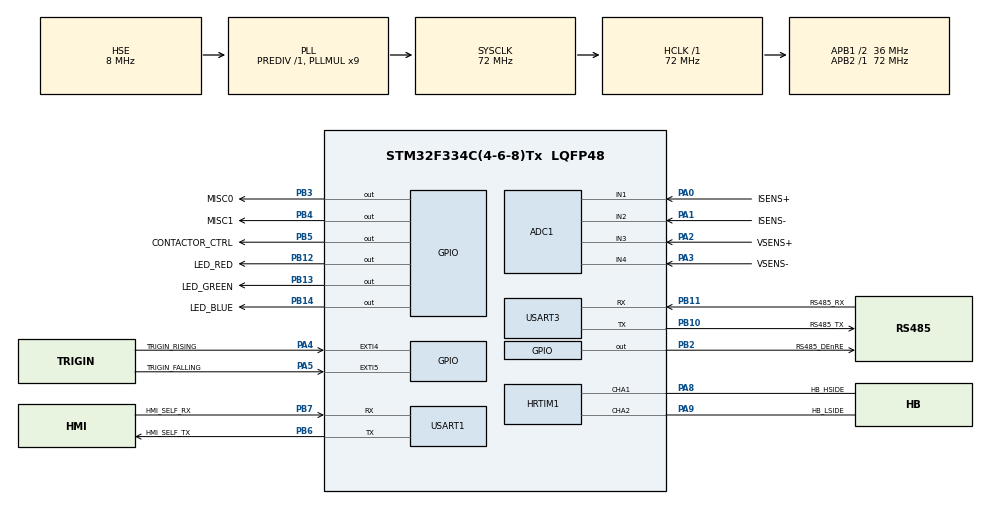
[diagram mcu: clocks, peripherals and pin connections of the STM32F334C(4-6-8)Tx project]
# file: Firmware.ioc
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ADC1.Channel-0\#ChannelRegularConversion=ADC_CHANNEL_1
ADC1.Channel-1\#ChannelRegularConversion=ADC_CHANNEL_3
ADC1.ClockPrescaler=ADC_CLOCK_ASYNC_DIV1
ADC1.DMAContinuousRequests=ENABLE
ADC1.EOCSelection=ADC_EOC_SEQ_CONV
ADC1.ExternalTrigConv=ADC_EXTERNALTRIGCONVHRTIM_TRG1
ADC1.NbrOfConversion=2
ADC1.NbrOfConversionFlag=1
ADC1.Offset-0\#ChannelRegularConversion=0
ADC1.Offset-1\#ChannelRegularConversion=0
ADC1.OffsetNumber-0\#ChannelRegularConversion=ADC_OFFSET_NONE
ADC1.OffsetNumber-1\#ChannelRegularConversion=ADC_OFFSET_NONE
ADC1.Rank-0\#ChannelRegularConversion=1
ADC1.Rank-1\#ChannelRegularConversion=2
ADC1.SamplingTime-0\#ChannelRegularConversion=ADC_SAMPLETIME_19CYCLES_5
ADC1.SamplingTime-1\#ChannelRegularConversion=ADC_SAMPLETIME_19CYCLES_5
ADC1.SingleDiff-0\#ChannelRegularConversion=ADC_DIFFERENTIAL_ENDED
ADC1.SingleDiff-1\#ChannelRegularConversion=ADC_DIFFERENTIAL_ENDED
ADC1.SubFamily=STM32F334x8
ADC1.master=1
Dma.ADC1.0.Direction=DMA_PERIPH_TO_MEMORY
Dma.ADC1.0.Instance=DMA1_Channel1
Dma.ADC1.0.MemDataAlignment=DMA_MDATAALIGN_HALFWORD
Dma.ADC1.0.MemInc=DMA_MINC_ENABLE
Dma.ADC1.0.Mode=DMA_CIRCULAR
Dma.ADC1.0.PeriphDataAlignment=DMA_PDATAALIGN_HALFWORD
Dma.ADC1.0.PeriphInc=DMA_PINC_DISABLE
Dma.ADC1.0.Priority=DMA_PRIORITY_MEDIUM
Dma.Request0=ADC1
HRTIM1.ADCTrigger1_Source1=HRTIM_ADCTRIGGEREVENT13_TIMERB_CMP2
HRTIM1.ADCTrigger_Id1=HRTIM_ADCTRIGGER_1
HRTIM1.ADCTrigger_Id2=__NULL
HRTIM1.ADCTrigger_Id3=__NULL
HRTIM1.CompareUnit1-No_output_TB=__NULL
HRTIM1.CompareUnit1-Output_TA1TA2=HRTIM_COMPAREUNIT_1
HRTIM1.CompareUnit2-No_output_TB=HRTIM_COMPAREUNIT_2
HRTIM1.CompareUnit2-Output_TA1TA2=HRTIM_COMPAREUNIT_2
HRTIM1.CompareValue1-Output_TA1TA2=0x0018
HRTIM1.CompareValue2-No_output_TB=0x8000
HRTIM1.Configuration_TA=Waveform
HRTIM1.DeadTimeInsertion-Output_TA1TA2=HRTIM_TIMDEADTIMEINSERTION_ENABLED
HRTIM1.Enable_FaultLine1=HRTIM_FAULTMODECTL_DISABLED
HRTIM1.FallingLock-Output_TA1TA2=HRTIM_TIMDEADTIME_FALLINGLOCK_READONLY
HRTIM1.FallingSign-Output_TA1TA2=HRTIM_TIMDEADTIME_FALLINGSIGN_POSITIVE
HRTIM1.FallingSignLock-Output_TA1TA2=HRTIM_TIMDEADTIME_FALLINGSIGNLOCK_READONLY
HRTIM1.FallingValue-Output_TA1TA2=144
HRTIM1.FaultEnable_Source1-No_output_TB=HRTIM_TIMFAULTENABLE_FAULT1
HRTIM1.FaultEnable_Source1-Output_TA1TA2=HRTIM_TIMFAULTENABLE_NONE
HRTIM1.FaultLevel1-Output_TA1TA2=HRTIM_OUTPUTFAULTLEVEL_NONE
HRTIM1.FaultLevel2-Output_TA1TA2=HRTIM_OUTPUTFAULTLEVEL_NONE
HRTIM1.FaultLock-Output_TA1TA2=HRTIM_TIMFAULTLOCK_READONLY
HRTIM1.Fault_Line1=__NULL
HRTIM1.Filter_FaultLine1=HRTIM_FAULTFILTER_12
HRTIM1.Lock_FaultLine1=HRTIM_FAULTLOCK_READONLY
HRTIM1.NumberADCTriggerSource1=1
HRTIM1.NumberFaultEnable-No_output_TB=0
HRTIM1.NumberFaultEnable-Output_TA1TA2=0
HRTIM1.NumberResetSource1-Output_TA1TA2=1
HRTIM1.NumberResetTrigger-No_output_TB=1
HRTIM1.NumberSetSource1-Output_TA1TA2=1
HRTIM1.NumberUpdateTrigger-No_output_TB=1
HRTIM1.ORingUpdateSource_ADCTrigger1=HRTIM_ADCTRIGGERUPDATE_TIMER_B
HRTIM1.Polarity1-Output_TA1TA2=HRTIM_OUTPUTPOLARITY_LOW
HRTIM1.Polarity2-Output_TA1TA2=HRTIM_OUTPUTPOLARITY_LOW
HRTIM1.PreloadEnable-No_output_TB=HRTIM_PRELOAD_ENABLED
HRTIM1.PreloadEnable-Output_TA1TA2=HRTIM_PRELOAD_ENABLED
HRTIM1.PrescalerDead-Output_TA1TA2=HRTIM_TIMDEADTIME_PRESCALERRATIO_DIV1
HRTIM1.PrescalerRatio_TA=HRTIM_PRESCALERRATIO_MUL8
HRTIM1.PrescalerRatio_TB=HRTIM_PRESCALERRATIO_MUL8
HRTIM1.ResetOutput1_Source1-Output_TA1TA2=HRTIM_OUTPUTRESET_TIMCMP2
HRTIM1.ResetTrigger1-No_output_TB=HRTIM_TIMRESETTRIGGER_OTHER1_CMP1
HRTIM1.ResetUpdate-No_output_TB=HRTIM_TIMUPDATEONRESET_DISABLED
HRTIM1.ResetUpdate-Output_TA1TA2=HRTIM_TIMUPDATEONRESET_ENABLED
HRTIM1.RisingLock-Output_TA1TA2=HRTIM_TIMDEADTIME_RISINGLOCK_READONLY
HRTIM1.RisingSignLock-Output_TA1TA2=HRTIM_TIMDEADTIME_RISINGSIGNLOCK_READONLY
HRTIM1.RisingValue-Output_TA1TA2=144
HRTIM1.SetOutput1_Source1-Output_TA1TA2=HRTIM_OUTPUTSET_TIMPER
HRTIM1.UpdateTrigger1-No_output_TB=HRTIM_TIMUPDATETRIGGER_TIMER_A
Mcu.Family=STM32F3
Mcu.Name=STM32F334C(4-6-8)Tx
Mcu.Package=LQFP48
Mcu.UserConstants=MCU_CLOCK_FREQ,72000000;TIM3_CLOCK_FREQ,MCU_CLOCK_FREQ;TIM3_PRESCALER,71;DEFAULT_LINE_FREQ,50
NVIC.DMA1_Channel1_IRQn=true\:1\:0\:true\:false\:true\:false\:true
NVIC.EXTI4_IRQn=true\:2\:0\:true\:false\:true\:true\:true
NVIC.EXTI9_5_IRQn=true\:2\:0\:true\:false\:true\:true\:true
NVIC.PriorityGroup=NVIC_PRIORITYGROUP_4
PA0.GPIO_Label=ISENS+
PA0.Mode=IN1-Differential
PA0.Signal=ADC1_IN1
PA1.GPIO_Label=ISENS-
PA1.Mode=IN1-Differential
PA1.Signal=ADC1_IN2
PA13.Mode=Serial_Wire
PA13.Signal=SYS_JTMS-SWDIO
PA14.Mode=Serial_Wire
PA14.Signal=SYS_JTCK-SWCLK
PA2.GPIO_Label=VSENS+
PA2.Mode=IN3-Differential
PA2.Signal=ADC1_IN3
PA3.GPIO_Label=VSENS-
PA3.Mode=IN3-Differential
PA3.Signal=ADC1_IN4
PA4.GPIO_Label=TRIGIN_RISING
PA4.GPIO_PuPd=GPIO_PULLDOWN
PA4.Signal=GPXTI4
PA5.GPIO_Label=TRIGIN_FALLING
PA5.GPIO_PuPd=GPIO_PULLDOWN
PA5.Signal=GPXTI5
PA8.GPIO_Label=HB_HSIDE
PA8.Mode=Output_TA1TA2
PA8.Signal=HRTIM1_CHA1
PA9.GPIO_Label=HB_LSIDE
PA9.Mode=Output_TA1TA2
PA9.Signal=HRTIM1_CHA2
PB10.GPIO_Label=RS485_TX
PB10.Mode=Asynchronous
PB10.Signal=USART3_TX
PB11.GPIO_Label=RS485_RX
PB11.Mode=Asynchronous
PB11.Signal=USART3_RX
PB12.GPIO_Label=LED_RED
PB12.Signal=GPIO_Output
PB13.GPIO_Label=LED_GREEN
PB13.Signal=GPIO_Output
PB14.GPIO_Label=LED_BLUE
PB14.Signal=GPIO_Output
PB2.GPIO_Label=RS485_DEnRE
PB2.GPIO_Speed=GPIO_SPEED_FREQ_MEDIUM
PB2.PinState=GPIO_PIN_RESET
PB2.Signal=GPIO_Output
PB3.GPIO_Label=MISC0
PB3.Signal=GPIO_Output
PB4.GPIO_Label=MISC1
PB4.Signal=GPIO_Output
PB5.GPIO_Label=CONTACTOR_CTRL
PB5.Signal=GPIO_Output
PB6.GPIO_Label=HMI_SELF_TX
PB6.Mode=Asynchronous
PB6.Signal=USART1_TX
PB7.GPIO_Label=HMI_SELF_RX
PB7.Mode=Asynchronous
PB7.Signal=USART1_RX
PF0\ /\ OSC_IN.Mode=HSE-External-Oscillator
PF0\ /\ OSC_IN.Signal=RCC_OSC_IN
PF1\ /\ OSC_OUT.Mode=HSE-External-Oscillator
PF1\ /\ OSC_OUT.Signal=RCC_OSC_OUT
ProjectManager.HeapSize=0x200
ProjectManager.StackSize=0x400
ProjectManager.TargetToolchain=Makefile
RCC.AHBFreq_Value=72000000
RCC.APB1CLKDivider=RCC_HCLK_DIV2
RCC.APB1Freq_Value=36000000
RCC.APB1TimFreq_Value=72000000
RCC.APB2Freq_Value=72000000
RCC.APB2TimFreq_Value=72000000
RCC.CortexFreq_Value=72000000
RCC.HCLKFreq_Value=72000000
RCC.HRTIMSelection=RCC_HRTIM1CLK_PLLCLK
RCC.HSE_VALUE=8000000
RCC.HSI_VALUE=8000000
RCC.LSE_VALUE=32768
RCC.PLLMUL=RCC_PLL_MUL9
RCC.PLLSourceVirtual=RCC_PLLSOURCE_HSE
RCC.SYSCLKFreq_VALUE=72000000
RCC.SYSCLKSourceVirtual=RCC_SYSCLKSOURCE_PLLCLK
USART1.VirtualMode-Asynchronous=VM_ASYNC
USART3.VirtualMode-Asynchronous=VM_ASYNC
VP_HRTIM1_VS_hrtimTimerBNoOutput.Mode=No_output_TB
board=custom

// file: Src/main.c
/* USER CODE BEGIN Header */
/**
  ******************************************************************************
  * @file           : main.c
  * @brief          : Main program body
  ******************************************************************************
  * @attention
  *
  * <h2><center>&copy; Copyright (c) 2020 STMicroelectronics.
  * All rights reserved.</center></h2>
  *
  * This software component is licensed by ST under BSD 3-Clause license,
  * the "License"; You may not use this file except in compliance with the
  * License. You may obtain a copy of the License at:
  *                        opensource.org/licenses/BSD-3-Clause
  *
  ******************************************************************************
  */
  /* USER CODE END Header */

  /* Includes ------------------------------------------------------------------*/
#include "main.h"
#include "lattice.h"
#include "eeprom_emulator.h"

ADC_HandleTypeDef hadc1;
DMA_HandleTypeDef hdma_adc1;

HRTIM_HandleTypeDef hhrtim1;

UART_HandleTypeDef huart1;
UART_HandleTypeDef huart3;

void SystemClock_Config(void);
static void MX_GPIO_Init(void);
static void MX_DMA_Init(void);
static void MX_HRTIM1_Init(void);
static void MX_ADC1_Init(void);
static void MX_USART1_UART_Init(void);
static void MX_USART3_UART_Init(void);

int main(void)
{

    /* MCU Configuration--------------------------------------------------------*/

    /* Reset of all peripherals, Initializes the Flash interface and the Systick. */
    HAL_Init();

    /* Configure the system clock */
    SystemClock_Config();

    /* Initialize all configured peripherals */
    MX_GPIO_Init();
    MX_DMA_Init();
    MX_HRTIM1_Init();
    MX_ADC1_Init();
    MX_USART1_UART_Init();
    MX_USART3_UART_Init();

    /* USER CODE BEGIN 2 */
    HAL_Delay(STARTUP_DELAY_IN_MS);

    // Turn on the contactor.
    EepromEmulator_Init();
    HAL_GPIO_WritePin(CONTACTOR_CTRL_GPIO_Port, CONTACTOR_CTRL_Pin, GPIO_PIN_RESET);
    Lattice_Start();
    /* USER CODE END 2 */

    /* Infinite loop */
    /* USER CODE BEGIN WHILE */
    while (1)
    {
        Lattice_Execute();
        /* USER CODE END WHILE */

    }
}

void SystemClock_Config(void)
{
    RCC_OscInitTypeDef RCC_OscInitStruct ={ 0 };
    RCC_ClkInitTypeDef RCC_ClkInitStruct ={ 0 };
    RCC_PeriphCLKInitTypeDef PeriphClkInit ={ 0 };

    /** Initializes the CPU, AHB and APB busses clocks
    */
    RCC_OscInitStruct.OscillatorType = RCC_OSCILLATORTYPE_HSE;
    RCC_OscInitStruct.HSEState = RCC_HSE_ON;
    RCC_OscInitStruct.HSEPredivValue = RCC_HSE_PREDIV_DIV1;
    RCC_OscInitStruct.HSIState = RCC_HSI_ON;
    RCC_OscInitStruct.PLL.PLLState = RCC_PLL_ON;
    RCC_OscInitStruct.PLL.PLLSource = RCC_PLLSOURCE_HSE;
    RCC_OscInitStruct.PLL.PLLMUL = RCC_PLL_MUL9;
    if (HAL_RCC_OscConfig(&RCC_OscInitStruct) != HAL_OK)
    {
        Error_Handler();
    }
    /** Initializes the CPU, AHB and APB busses clocks
    */
    RCC_ClkInitStruct.ClockType = RCC_CLOCKTYPE_HCLK | RCC_CLOCKTYPE_SYSCLK | RCC_CLOCKTYPE_PCLK1 | RCC_CLOCKTYPE_PCLK2;
    RCC_ClkInitStruct.SYSCLKSource = RCC_SYSCLKSOURCE_PLLCLK;
    RCC_ClkInitStruct.AHBCLKDivider = RCC_SYSCLK_DIV1;
    RCC_ClkInitStruct.APB1CLKDivider = RCC_HCLK_DIV2;
    RCC_ClkInitStruct.APB2CLKDivider = RCC_HCLK_DIV1;

    if (HAL_RCC_ClockConfig(&RCC_ClkInitStruct, FLASH_LATENCY_2) != HAL_OK)
    {
        Error_Handler();
    }
    PeriphClkInit.PeriphClockSelection = RCC_PERIPHCLK_HRTIM1 | RCC_PERIPHCLK_USART1;
    PeriphClkInit.Usart1ClockSelection = RCC_USART1CLKSOURCE_PCLK1;
    PeriphClkInit.Hrtim1ClockSelection = RCC_HRTIM1CLK_PLLCLK;
    if (HAL_RCCEx_PeriphCLKConfig(&PeriphClkInit) != HAL_OK)
    {
        Error_Handler();
    }
}

static void MX_ADC1_Init(void)
{

    ADC_MultiModeTypeDef multimode ={ 0 };
    ADC_ChannelConfTypeDef sConfig ={ 0 };

    /** Common config
    */
    hadc1.Instance = ADC1;
    hadc1.Init.ClockPrescaler = ADC_CLOCK_SYNC_PCLK_DIV2;
    hadc1.Init.Resolution = ADC_RESOLUTION_12B;
    hadc1.Init.ScanConvMode = ADC_SCAN_ENABLE;
    hadc1.Init.ContinuousConvMode = DISABLE;
    hadc1.Init.DiscontinuousConvMode = DISABLE;
    hadc1.Init.ExternalTrigConvEdge = ADC_EXTERNALTRIGCONVEDGE_RISING;
    hadc1.Init.ExternalTrigConv = ADC_EXTERNALTRIGCONVHRTIM_TRG1;
    hadc1.Init.DataAlign = ADC_DATAALIGN_RIGHT;
    hadc1.Init.NbrOfConversion = 2;
    hadc1.Init.DMAContinuousRequests = ENABLE;
    hadc1.Init.EOCSelection = ADC_EOC_SEQ_CONV;
    hadc1.Init.LowPowerAutoWait = DISABLE;
    hadc1.Init.Overrun = ADC_OVR_DATA_OVERWRITTEN;
    if (HAL_ADC_Init(&hadc1) != HAL_OK)
    {
        Error_Handler();
    }
    /** Configure the ADC multi-mode
    */
    multimode.Mode = ADC_MODE_INDEPENDENT;
    if (HAL_ADCEx_MultiModeConfigChannel(&hadc1, &multimode) != HAL_OK)
    {
        Error_Handler();
    }
    /** Configure Regular Channel
    */
    sConfig.Channel = ADC_CHANNEL_1;
    sConfig.Rank = ADC_REGULAR_RANK_1;
    sConfig.SingleDiff = ADC_DIFFERENTIAL_ENDED;
    sConfig.SamplingTime = ADC_SAMPLETIME_19CYCLES_5;
    sConfig.OffsetNumber = ADC_OFFSET_NONE;
    sConfig.Offset = 0;
    if (HAL_ADC_ConfigChannel(&hadc1, &sConfig) != HAL_OK)
    {
        Error_Handler();
    }
    /** Configure Regular Channel
    */
    sConfig.Channel = ADC_CHANNEL_3;
    sConfig.Rank = ADC_REGULAR_RANK_2;
    if (HAL_ADC_ConfigChannel(&hadc1, &sConfig) != HAL_OK)
    {
        Error_Handler();
    }
}

static void MX_HRTIM1_Init(void)
{

    HRTIM_ADCTriggerCfgTypeDef pADCTriggerCfg ={ 0 };
    HRTIM_TimeBaseCfgTypeDef pTimeBaseCfg ={ 0 };
    HRTIM_TimerCfgTypeDef pTimerCfg ={ 0 };
    HRTIM_CompareCfgTypeDef pCompareCfg ={ 0 };
    HRTIM_DeadTimeCfgTypeDef pDeadTimeCfg ={ 0 };
    HRTIM_OutputCfgTypeDef pOutputCfg ={ 0 };

    hhrtim1.Instance = HRTIM1;
    hhrtim1.Init.HRTIMInterruptResquests = HRTIM_IT_NONE;
    hhrtim1.Init.SyncOptions = HRTIM_SYNCOPTION_NONE;
    if (HAL_HRTIM_Init(&hhrtim1) != HAL_OK)
    {
        Error_Handler();
    }
    if (HAL_HRTIM_DLLCalibrationStart(&hhrtim1, HRTIM_CALIBRATIONRATE_14) != HAL_OK)
    {
        Error_Handler();
    }
    if (HAL_HRTIM_PollForDLLCalibration(&hhrtim1, 10) != HAL_OK)
    {
        Error_Handler();
    }
    pADCTriggerCfg.UpdateSource = HRTIM_ADCTRIGGERUPDATE_TIMER_B;
    pADCTriggerCfg.Trigger = HRTIM_ADCTRIGGEREVENT13_TIMERB_CMP2;
    if (HAL_HRTIM_ADCTriggerConfig(&hhrtim1, HRTIM_ADCTRIGGER_1, &pADCTriggerCfg) != HAL_OK)
    {
        Error_Handler();
    }
    pTimeBaseCfg.Period = 0xFFF7;
    pTimeBaseCfg.RepetitionCounter = 0x00;
    pTimeBaseCfg.PrescalerRatio = HRTIM_PRESCALERRATIO_MUL8;
    pTimeBaseCfg.Mode = HRTIM_MODE_CONTINUOUS;
    if (HAL_HRTIM_TimeBaseConfig(&hhrtim1, HRTIM_TIMERINDEX_TIMER_A, &pTimeBaseCfg) != HAL_OK)
    {
        Error_Handler();
    }
    pTimerCfg.InterruptRequests = HRTIM_TIM_IT_NONE;
    pTimerCfg.DMARequests = HRTIM_TIM_DMA_NONE;
    pTimerCfg.DMASrcAddress = 0x0000;
    pTimerCfg.DMADstAddress = 0x0000;
    pTimerCfg.DMASize = 0x1;
    pTimerCfg.HalfModeEnable = HRTIM_HALFMODE_DISABLED;
    pTimerCfg.StartOnSync = HRTIM_SYNCSTART_DISABLED;
    pTimerCfg.ResetOnSync = HRTIM_SYNCRESET_DISABLED;
    pTimerCfg.DACSynchro = HRTIM_DACSYNC_NONE;
    pTimerCfg.PreloadEnable = HRTIM_PRELOAD_ENABLED;
    pTimerCfg.UpdateGating = HRTIM_UPDATEGATING_INDEPENDENT;
    pTimerCfg.BurstMode = HRTIM_TIMERBURSTMODE_MAINTAINCLOCK;
    pTimerCfg.RepetitionUpdate = HRTIM_UPDATEONREPETITION_DISABLED;
    pTimerCfg.PushPull = HRTIM_TIMPUSHPULLMODE_DISABLED;
    pTimerCfg.FaultEnable = HRTIM_TIMFAULTENABLE_NONE;
    pTimerCfg.FaultLock = HRTIM_TIMFAULTLOCK_READONLY;
    pTimerCfg.DeadTimeInsertion = HRTIM_TIMDEADTIMEINSERTION_ENABLED;
    pTimerCfg.DelayedProtectionMode = HRTIM_TIMER_A_B_C_DELAYEDPROTECTION_DISABLED;
    pTimerCfg.UpdateTrigger = HRTIM_TIMUPDATETRIGGER_NONE;
    pTimerCfg.ResetTrigger = HRTIM_TIMRESETTRIGGER_NONE;
    pTimerCfg.ResetUpdate = HRTIM_TIMUPDATEONRESET_ENABLED;
    if (HAL_HRTIM_WaveformTimerConfig(&hhrtim1, HRTIM_TIMERINDEX_TIMER_A, &pTimerCfg) != HAL_OK)
    {
        Error_Handler();
    }
    pTimerCfg.DMASrcAddress = 0x0000;
    pTimerCfg.DMADstAddress = 0x0000;
    pTimerCfg.DMASize = 0x1;
    pTimerCfg.FaultLock = HRTIM_TIMFAULTLOCK_READWRITE;
    pTimerCfg.DeadTimeInsertion = HRTIM_TIMDEADTIMEINSERTION_DISABLED;
    pTimerCfg.UpdateTrigger = HRTIM_TIMUPDATETRIGGER_TIMER_A;
    pTimerCfg.ResetTrigger = HRTIM_TIMRESETTRIGGER_OTHER1_CMP1;
    pTimerCfg.ResetUpdate = HRTIM_TIMUPDATEONRESET_DISABLED;
    if (HAL_HRTIM_WaveformTimerConfig(&hhrtim1, HRTIM_TIMERINDEX_TIMER_B, &pTimerCfg) != HAL_OK)
    {
        Error_Handler();
    }
    pCompareCfg.CompareValue = 0x0018;
    if (HAL_HRTIM_WaveformCompareConfig(&hhrtim1, HRTIM_TIMERINDEX_TIMER_A, HRTIM_COMPAREUNIT_1, &pCompareCfg) != HAL_OK)
    {
        Error_Handler();
    }
    pCompareCfg.CompareValue = 0xFFF7;
    pCompareCfg.AutoDelayedMode = HRTIM_AUTODELAYEDMODE_REGULAR;
    pCompareCfg.AutoDelayedTimeout = 0x0000;

    if (HAL_HRTIM_WaveformCompareConfig(&hhrtim1, HRTIM_TIMERINDEX_TIMER_A, HRTIM_COMPAREUNIT_2, &pCompareCfg) != HAL_OK)
    {
        Error_Handler();
    }
    pCompareCfg.CompareValue = 0x8000;
    pCompareCfg.AutoDelayedTimeout = 0x0000;

    if (HAL_HRTIM_WaveformCompareConfig(&hhrtim1, HRTIM_TIMERINDEX_TIMER_B, HRTIM_COMPAREUNIT_2, &pCompareCfg) != HAL_OK)
    {
        Error_Handler();
    }
    pDeadTimeCfg.Prescaler = HRTIM_TIMDEADTIME_PRESCALERRATIO_DIV1;
    pDeadTimeCfg.RisingValue = 360;
    pDeadTimeCfg.RisingSign = HRTIM_TIMDEADTIME_RISINGSIGN_POSITIVE;
    pDeadTimeCfg.RisingLock = HRTIM_TIMDEADTIME_RISINGLOCK_READONLY;
    pDeadTimeCfg.RisingSignLock = HRTIM_TIMDEADTIME_RISINGSIGNLOCK_READONLY;
    pDeadTimeCfg.FallingValue = 332;
    pDeadTimeCfg.FallingSign = HRTIM_TIMDEADTIME_FALLINGSIGN_POSITIVE;
    pDeadTimeCfg.FallingLock = HRTIM_TIMDEADTIME_FALLINGLOCK_READONLY;
    pDeadTimeCfg.FallingSignLock = HRTIM_TIMDEADTIME_FALLINGSIGNLOCK_READONLY;
    if (HAL_HRTIM_DeadTimeConfig(&hhrtim1, HRTIM_TIMERINDEX_TIMER_A, &pDeadTimeCfg) != HAL_OK)
    {
        Error_Handler();
    }
    pOutputCfg.Polarity = HRTIM_OUTPUTPOLARITY_LOW;
    pOutputCfg.SetSource = HRTIM_OUTPUTSET_TIMPER;
    pOutputCfg.ResetSource = HRTIM_OUTPUTRESET_TIMCMP2;
    pOutputCfg.IdleMode = HRTIM_OUTPUTIDLEMODE_NONE;
    pOutputCfg.IdleLevel = HRTIM_OUTPUTIDLELEVEL_INACTIVE;
    pOutputCfg.FaultLevel = HRTIM_OUTPUTFAULTLEVEL_NONE;
    pOutputCfg.ChopperModeEnable = HRTIM_OUTPUTCHOPPERMODE_DISABLED;
    pOutputCfg.BurstModeEntryDelayed = HRTIM_OUTPUTBURSTMODEENTRY_REGULAR;
    if (HAL_HRTIM_WaveformOutputConfig(&hhrtim1, HRTIM_TIMERINDEX_TIMER_A, HRTIM_OUTPUT_TA1, &pOutputCfg) != HAL_OK)
    {
        Error_Handler();
    }
    pOutputCfg.SetSource = HRTIM_OUTPUTSET_NONE;
    pOutputCfg.ResetSource = HRTIM_OUTPUTRESET_NONE;
    if (HAL_HRTIM_WaveformOutputConfig(&hhrtim1, HRTIM_TIMERINDEX_TIMER_A, HRTIM_OUTPUT_TA2, &pOutputCfg) != HAL_OK)
    {
        Error_Handler();
    }
    if (HAL_HRTIM_TimeBaseConfig(&hhrtim1, HRTIM_TIMERINDEX_TIMER_B, &pTimeBaseCfg) != HAL_OK)
    {
        Error_Handler();
    }
    HAL_HRTIM_MspPostInit(&hhrtim1);
}

static void MX_USART1_UART_Init(void)
{

    huart1.Instance = USART1;
    huart1.Init.BaudRate = 38400;
    huart1.Init.WordLength = UART_WORDLENGTH_8B;
    huart1.Init.StopBits = UART_STOPBITS_1;
    huart1.Init.Parity = UART_PARITY_NONE;
    huart1.Init.Mode = UART_MODE_TX_RX;
    huart1.Init.HwFlowCtl = UART_HWCONTROL_NONE;
    huart1.Init.OverSampling = UART_OVERSAMPLING_16;
    huart1.Init.OneBitSampling = UART_ONE_BIT_SAMPLE_DISABLE;
    huart1.AdvancedInit.AdvFeatureInit = UART_ADVFEATURE_NO_INIT;
    if (HAL_UART_Init(&huart1) != HAL_OK)
    {
        Error_Handler();
    }
}

static void MX_USART3_UART_Init(void)
{

    huart3.Instance = USART3;
    huart3.Init.BaudRate = 38400;
    huart3.Init.WordLength = UART_WORDLENGTH_8B;
    huart3.Init.StopBits = UART_STOPBITS_1;
    huart3.Init.Parity = UART_PARITY_NONE;
    huart3.Init.Mode = UART_MODE_TX_RX;
    huart3.Init.HwFlowCtl = UART_HWCONTROL_NONE;
    huart3.Init.OverSampling = UART_OVERSAMPLING_16;
    huart3.Init.OneBitSampling = UART_ONE_BIT_SAMPLE_DISABLE;
    huart3.AdvancedInit.AdvFeatureInit = UART_ADVFEATURE_NO_INIT;
    if (HAL_UART_Init(&huart3) != HAL_OK)
    {
        Error_Handler();
    }
}

static void MX_DMA_Init(void)
{
    /* DMA controller clock enable */
    __HAL_RCC_DMA1_CLK_ENABLE();

    /* DMA interrupt init */
    /* DMA1_Channel1_IRQn interrupt configuration */
    HAL_NVIC_SetPriority(DMA1_Channel1_IRQn, 1, 0);
    HAL_NVIC_EnableIRQ(DMA1_Channel1_IRQn);
}

static void MX_GPIO_Init(void)
{
    GPIO_InitTypeDef GPIO_InitStruct ={ 0 };

    /* GPIO Ports Clock Enable */
    __HAL_RCC_GPIOF_CLK_ENABLE();
    __HAL_RCC_GPIOA_CLK_ENABLE();
    __HAL_RCC_GPIOB_CLK_ENABLE();

    /*Configure GPIO pin Output Level */
    HAL_GPIO_WritePin(GPIOB, RS485_DEnRE_Pin | LED_RED_Pin | LED_GREEN_Pin | LED_BLUE_Pin | MISC0_Pin | MISC1_Pin, GPIO_PIN_RESET);
    HAL_GPIO_WritePin(CONTACTOR_CTRL_GPIO_Port, CONTACTOR_CTRL_Pin, GPIO_PIN_SET);

    /*Configure GPIO pins : TRIGIN_RISING_Pin */
    GPIO_InitStruct.Pin = TRIGIN_RISING_Pin;
    GPIO_InitStruct.Mode = GPIO_MODE_IT_RISING;
    GPIO_InitStruct.Pull = GPIO_PULLDOWN;
    HAL_GPIO_Init(GPIOA, &GPIO_InitStruct);

    /*Configure GPIO pins : TRIGIN_FALLING_Pin */
    GPIO_InitStruct.Pin = TRIGIN_FALLING_Pin;
    GPIO_InitStruct.Mode = GPIO_MODE_IT_FALLING;
    GPIO_InitStruct.Pull = GPIO_PULLDOWN;
    HAL_GPIO_Init(GPIOA, &GPIO_InitStruct);

    /*Configure GPIO pins : RS485_DEnRE_Pin */
    GPIO_InitStruct.Pin = RS485_DEnRE_Pin;
    GPIO_InitStruct.Mode = GPIO_MODE_OUTPUT_PP;
    GPIO_InitStruct.Pull = GPIO_NOPULL;
    GPIO_InitStruct.Speed = GPIO_SPEED_FREQ_MEDIUM;
    HAL_GPIO_Init(GPIOB, &GPIO_InitStruct);

    /*Configure GPIO pins : LED_RED_Pin LED_GREEN_Pin LED_BLUE_Pin MISC0_Pin
                             MISC1_Pin MISC2_Pin */
    GPIO_InitStruct.Pin = LED_RED_Pin | LED_GREEN_Pin | LED_BLUE_Pin | MISC0_Pin | MISC1_Pin | CONTACTOR_CTRL_Pin;
    GPIO_InitStruct.Mode = GPIO_MODE_OUTPUT_PP;
    GPIO_InitStruct.Pull = GPIO_NOPULL;
    GPIO_InitStruct.Speed = GPIO_SPEED_FREQ_LOW;
    HAL_GPIO_Init(GPIOB, &GPIO_InitStruct);

    /* EXTI interrupt init*/
    HAL_NVIC_SetPriority(EXTI4_IRQn, 2, 0);
    HAL_NVIC_EnableIRQ(EXTI4_IRQn);

    HAL_NVIC_SetPriority(EXTI9_5_IRQn, 2, 0);
    HAL_NVIC_EnableIRQ(EXTI9_5_IRQn);
}

/* USER CODE BEGIN 4 */
void Lattice_StatusChangeCb(Lattice_Status_t *status)
{
}

void HAL_GPIO_EXTI_Callback(uint16_t GPIO_Pin)
{
    if (GPIO_Pin == TRIGIN_RISING_Pin)
    {
        Lattice_CmdPowerOutput(TRUE);
    }

    if (GPIO_Pin == TRIGIN_FALLING_Pin)
    {
        Lattice_CmdPowerOutput(FALSE);
    }
}

/* USER CODE END 4 */

void Error_Handler(void)
{
}

/************************ (C) COPYRIGHT STMicroelectronics *****END OF FILE****/
